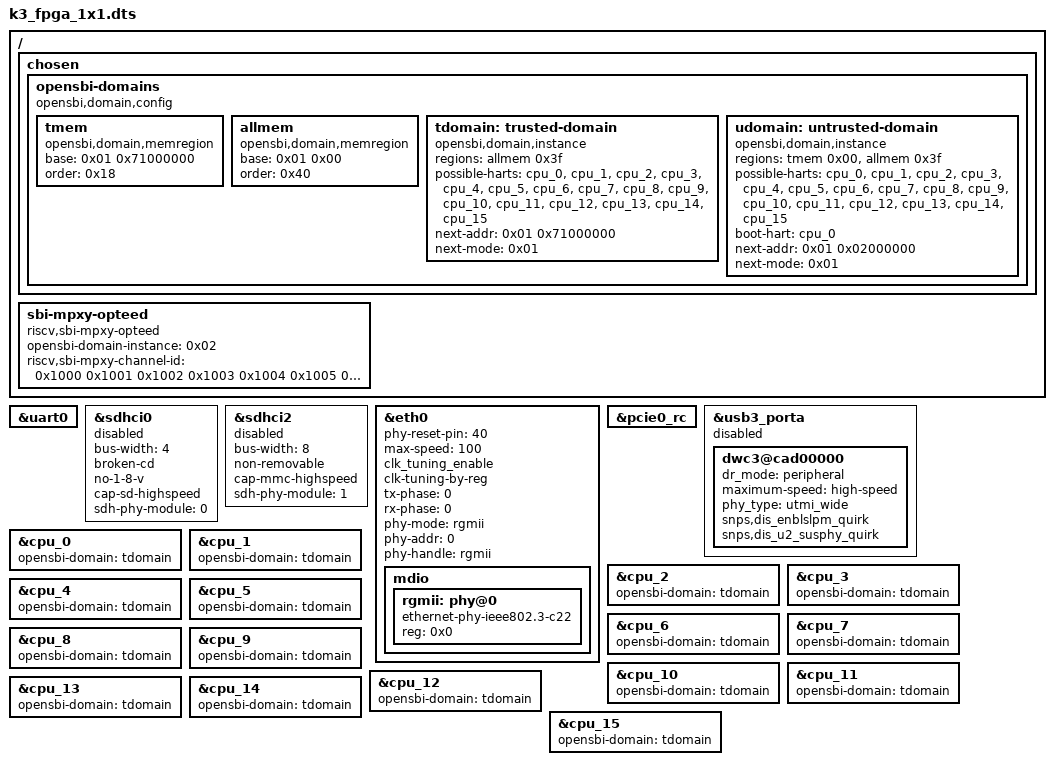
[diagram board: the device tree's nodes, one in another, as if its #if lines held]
// SPDX-License-Identifier: GPL-2.0
/*
 * finch board's base device tree configure.
 *
 * Copyright (C) 2025 SPACEMIT Micro Limited
 */

#include "k3.dtsi"
#include "k3-pinctrl.dtsi"
#include "k3_spm8821.dtsi"
#include "k3_is6608.dtsi"

&uart0 {
	status = "okay";
};

&sdhci0 {
	bus-width = <4>;
	broken-cd;
	no-1-8-v;
	cap-sd-highspeed;
	sdh-phy-module = <0>;
	status = "disabled";
};

/* eMMC */
&sdhci2 {
	bus-width = <8>;
	non-removable;
	cap-mmc-highspeed;
	sdh-phy-module = <1>;
	status = "disabled";
};

&eth0 {
	phy-reset-pin = <40>;
	max-speed = <100>;
	clk_tuning_enable;
	clk-tuning-by-reg;
	tx-phase = <0>;
	rx-phase = <0>;

	phy-mode = "rgmii";
	phy-addr = <0>;
	phy-handle = <&rgmii>;

	status = "okay";

	mdio {
		#address-cells = <0x1>;
		#size-cells = <0x0>;
		rgmii: phy@0 {
			compatible = "ethernet-phy-ieee802.3-c22";
			device_type = "ethernet-phy";
			reg = <0x0>;
		};
	};
};

&pcie0_rc{
	status = "okay";
};

&usb3_porta {
	status = "disabled";
	u-boot,dm-spl;
	dwc3@cad00000 {
		dr_mode = "peripheral";
		maximum-speed = "high-speed";
		phy_type = "utmi_wide";
		snps,dis_enblslpm_quirk;
		snps,dis_u2_susphy_quirk;
		u-boot,dm-spl;
	};
};

#ifdef CONFIG_RISCV_OPTEE_SUPPORT
/ {
	chosen {
		opensbi-domains {
			compatible = "opensbi,domain,config";

			tmem: tmem {
				compatible = "opensbi,domain,memregion";
				base = <0x01 0x71000000>;
				order = <0x18>;
			};

			allmem: allmem {
				compatible = "opensbi,domain,memregion";
				base = <0x01 0x00>;
				order = <0x40>;
			};

			tdomain: trusted-domain {
				compatible = "opensbi,domain,instance";
				regions = <&allmem 0x3f>;
				possible-harts = <&cpu_0 &cpu_1 &cpu_2 &cpu_3
					&cpu_4 &cpu_5 &cpu_6 &cpu_7
					&cpu_8 &cpu_9 &cpu_10 &cpu_11
					&cpu_12 &cpu_13 &cpu_14 &cpu_15>;
				next-addr = <0x01 0x71000000>;
				next-mode = <0x01>;
				phandle = <0x02>;
			};

			udomain: untrusted-domain {
				compatible = "opensbi,domain,instance";
				regions = <&tmem 0x00>, <&allmem 0x3f>;
				possible-harts = <&cpu_0 &cpu_1 &cpu_2 &cpu_3
					&cpu_4 &cpu_5 &cpu_6 &cpu_7
					&cpu_8 &cpu_9 &cpu_10 &cpu_11
					&cpu_12 &cpu_13 &cpu_14 &cpu_15>;
				boot-hart = <&cpu_0>;
				next-addr = <0x01 0x02000000>;
				next-mode = <0x01>;
			};
		};
	};

	sbi-mpxy-opteed {
		opensbi-domain-instance = <0x02>;
		riscv,sbi-mpxy-channel-id = <0x1000 0x1001 0x1002 0x1003
					0x1004 0x1005 0x1006 0x1007
					0x1008 0x1009 0x100a 0x100b
					0x100c 0x100d 0x100e 0x100f>;
		compatible = "riscv,sbi-mpxy-opteed";
	};
};

&cpu_0 {
	opensbi-domain = <&tdomain>;
};
&cpu_1 {
	opensbi-domain = <&tdomain>;
};
&cpu_2 {
	opensbi-domain = <&tdomain>;
};
&cpu_3 {
	opensbi-domain = <&tdomain>;
};
&cpu_4 {
	opensbi-domain = <&tdomain>;
};
&cpu_5 {
	opensbi-domain = <&tdomain>;
};
&cpu_6 {
	opensbi-domain = <&tdomain>;
};
&cpu_7 {
	opensbi-domain = <&tdomain>;
};
&cpu_8 {
	opensbi-domain = <&tdomain>;
};
&cpu_9 {
	opensbi-domain = <&tdomain>;
};
&cpu_10 {
	opensbi-domain = <&tdomain>;
};
&cpu_11 {
	opensbi-domain = <&tdomain>;
};
&cpu_12 {
	opensbi-domain = <&tdomain>;
};
&cpu_13 {
	opensbi-domain = <&tdomain>;
};
&cpu_14 {
	opensbi-domain = <&tdomain>;
};
&cpu_15 {
	opensbi-domain = <&tdomain>;
};
#endif
